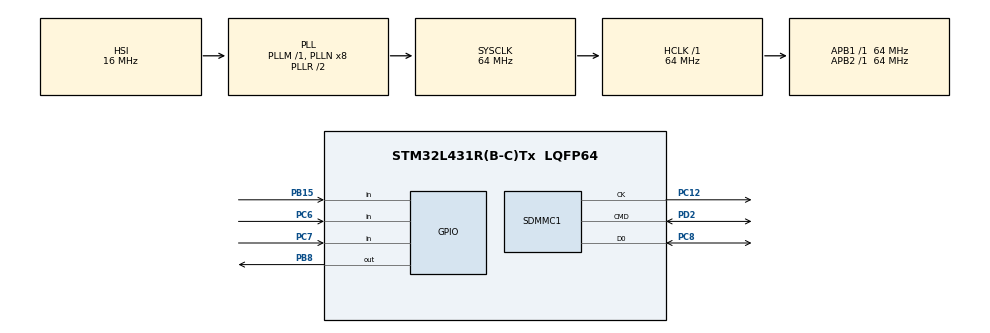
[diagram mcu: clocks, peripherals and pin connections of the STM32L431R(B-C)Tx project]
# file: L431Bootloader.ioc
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FATFS._FS_LOCK=0
FATFS._FS_MINIMIZE=3
FATFS._FS_NORTC=0
FATFS._FS_READONLY=1
FATFS._FS_TINY=1
FATFS._USE_FASTSEEK=0
FATFS._USE_LFN=0
FATFS._USE_MKFS=0
FATFS._USE_STRFUNC=0
Mcu.Family=STM32L4
Mcu.Name=STM32L431R(B-C)Tx
Mcu.Package=LQFP64
NVIC.PriorityGroup=NVIC_PRIORITYGROUP_4
PA13\ (JTMS-SWDIO).Mode=Trace_Asynchronous_SW
PA13\ (JTMS-SWDIO).Signal=SYS_JTMS-SWDIO
PA14\ (JTCK-SWCLK).Mode=Trace_Asynchronous_SW
PA14\ (JTCK-SWCLK).Signal=SYS_JTCK-SWCLK
PB15.Signal=GPIO_Input
PB3\ (JTDO-TRACESWO).Mode=Trace_Asynchronous_SW
PB3\ (JTDO-TRACESWO).Signal=SYS_JTDO-SWO
PB8.Signal=GPIO_Output
PC12.Mode=SD_1_bit
PC12.Signal=SDMMC1_CK
PC6.Signal=GPIO_Input
PC7.Signal=GPIO_Input
PC8.Mode=SD_1_bit
PC8.Signal=SDMMC1_D0
PD2.Mode=SD_1_bit
PD2.Signal=SDMMC1_CMD
ProjectManager.HeapSize=0x200
ProjectManager.StackSize=0x400
ProjectManager.TargetToolchain=STM32CubeIDE
RCC.ADCFreq_Value=64000000
RCC.AHBFreq_Value=64000000
RCC.APB1Freq_Value=64000000
RCC.APB1TimFreq_Value=64000000
RCC.APB2Freq_Value=64000000
RCC.APB2TimFreq_Value=64000000
RCC.CK48CLockSelection=RCC_USBCLKSOURCE_PLL
RCC.CortexFreq_Value=64000000
RCC.HCLKFreq_Value=64000000
RCC.HSE_VALUE=8000000
RCC.HSI48_VALUE=48000000
RCC.HSI_VALUE=16000000
RCC.LSE_VALUE=32768
RCC.MSI_VALUE=4000000
RCC.PLLQ=RCC_PLLQ_DIV8
RCC.PLLSourceVirtual=RCC_PLLSOURCE_HSI
RCC.SYSCLKFreq_VALUE=64000000
RCC.SYSCLKSource=RCC_SYSCLKSOURCE_PLLCLK
RCC.VCOOutputFreq_Value=128000000
SDMMC1.ClockDiv=2
VP_FATFS_VS_SDIO.Mode=SDIO
board=custom

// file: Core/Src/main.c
/* USER CODE BEGIN Header */
/**
  ******************************************************************************
  * @file           : main.c
  * @brief          : Main program body
  ******************************************************************************
  * @attention
  *
  * Copyright (c) 2026 STMicroelectronics.
  * All rights reserved.
  *
  * This software is licensed under terms that can be found in the LICENSE file
  * in the root directory of this software component.
  * If no LICENSE file comes with this software, it is provided AS-IS.
  *
  ******************************************************************************
  */
/* USER CODE END Header */
#include "main.h"
#include "fatfs.h"
#include "bootloader.h"
#include <stdio.h>
#include "flash_layout.h"

SD_HandleTypeDef hsd1;

void SystemClock_Config(void);
static void MX_GPIO_Init(void);
static void MX_SDMMC1_SD_Init(void);

/* USER CODE BEGIN 0 */

int _write(int file, char *ptr, int len) {
	if ((CoreDebug->DHCSR & CoreDebug_DHCSR_C_DEBUGEN_Msk) != 0) {
		for (int i = 0; i < len; i++) {
			ITM_SendChar((*ptr++));
		}

	}

	return len;
}

/* USER CODE END 0 */

int main(void)
{

  /* MCU Configuration--------------------------------------------------------*/

  /* Reset of all peripherals, Initializes the Flash interface and the Systick. */
  HAL_Init();

  /* Configure the system clock */
  SystemClock_Config();

  /* Initialize all configured peripherals */
  MX_GPIO_Init();
  MX_SDMMC1_SD_Init();
//  MX_FATFS_Init();
  /* USER CODE BEGIN 2 */

  initCRC();

  uint32_t file_crc;

  if (calculateFileCRC(&file_crc) == CRC_OK) {
	  //compare and then maybe flash.
	  uint32_t flash_crc = calculateFlashCRC();

	  if (file_crc != flash_crc) {
		  //THEN ERASE AND COPY
		  bootloader_reflash();
	  } else {
		  printf("Flash and Bootloader have same firmware!\r\n");
	  }

  } //else firmware not found or trouble mounting uSD
  //Boot normally!

  bootloader_jump_to_app();

  //BOOT NORMALLY

  /* USER CODE END 2 */

  /* Infinite loop */
  while (1)
  {

  }
}

void SystemClock_Config(void)
{
  RCC_OscInitTypeDef RCC_OscInitStruct = {0};
  RCC_ClkInitTypeDef RCC_ClkInitStruct = {0};

  /** Configure the main internal regulator output voltage
  */
  if (HAL_PWREx_ControlVoltageScaling(PWR_REGULATOR_VOLTAGE_SCALE1) != HAL_OK)
  {
    Error_Handler();
  }

  /** Initializes the RCC Oscillators according to the specified parameters
  * in the RCC_OscInitTypeDef structure.
  */
  RCC_OscInitStruct.OscillatorType = RCC_OSCILLATORTYPE_HSI;
  RCC_OscInitStruct.HSIState = RCC_HSI_ON;
  RCC_OscInitStruct.HSICalibrationValue = RCC_HSICALIBRATION_DEFAULT;
  RCC_OscInitStruct.PLL.PLLState = RCC_PLL_ON;
  RCC_OscInitStruct.PLL.PLLSource = RCC_PLLSOURCE_HSI;
  RCC_OscInitStruct.PLL.PLLM = 1;
  RCC_OscInitStruct.PLL.PLLN = 8;
  RCC_OscInitStruct.PLL.PLLP = RCC_PLLP_DIV7;
  RCC_OscInitStruct.PLL.PLLQ = RCC_PLLQ_DIV8;
  RCC_OscInitStruct.PLL.PLLR = RCC_PLLR_DIV2;
  if (HAL_RCC_OscConfig(&RCC_OscInitStruct) != HAL_OK)
  {
    Error_Handler();
  }

  /** Initializes the CPU, AHB and APB buses clocks
  */
  RCC_ClkInitStruct.ClockType = RCC_CLOCKTYPE_HCLK|RCC_CLOCKTYPE_SYSCLK
                              |RCC_CLOCKTYPE_PCLK1|RCC_CLOCKTYPE_PCLK2;
  RCC_ClkInitStruct.SYSCLKSource = RCC_SYSCLKSOURCE_PLLCLK;
  RCC_ClkInitStruct.AHBCLKDivider = RCC_SYSCLK_DIV1;
  RCC_ClkInitStruct.APB1CLKDivider = RCC_HCLK_DIV1;
  RCC_ClkInitStruct.APB2CLKDivider = RCC_HCLK_DIV1;

  if (HAL_RCC_ClockConfig(&RCC_ClkInitStruct, FLASH_LATENCY_3) != HAL_OK)
  {
    Error_Handler();
  }
}

static void MX_SDMMC1_SD_Init(void)
{

  hsd1.Instance = SDMMC1;
  hsd1.Init.ClockEdge = SDMMC_CLOCK_EDGE_RISING;
  hsd1.Init.ClockBypass = SDMMC_CLOCK_BYPASS_DISABLE;
  hsd1.Init.ClockPowerSave = SDMMC_CLOCK_POWER_SAVE_DISABLE;
  hsd1.Init.BusWide = SDMMC_BUS_WIDE_1B;
  hsd1.Init.HardwareFlowControl = SDMMC_HARDWARE_FLOW_CONTROL_DISABLE;
  hsd1.Init.ClockDiv = 2;

}

static void MX_GPIO_Init(void)
{
  GPIO_InitTypeDef GPIO_InitStruct = {0};

  /* GPIO Ports Clock Enable */
  __HAL_RCC_GPIOB_CLK_ENABLE();
  __HAL_RCC_GPIOC_CLK_ENABLE();
  __HAL_RCC_GPIOA_CLK_ENABLE();
  __HAL_RCC_GPIOD_CLK_ENABLE();

  /*Configure GPIO pin Output Level */
  HAL_GPIO_WritePin(GPIOB, GPIO_PIN_8, GPIO_PIN_RESET);

  /*Configure GPIO pin : PB15 */
  GPIO_InitStruct.Pin = GPIO_PIN_15;
  GPIO_InitStruct.Mode = GPIO_MODE_INPUT;
  GPIO_InitStruct.Pull = GPIO_NOPULL;
  HAL_GPIO_Init(GPIOB, &GPIO_InitStruct);

  /*Configure GPIO pins : PC6 PC7 */
  GPIO_InitStruct.Pin = GPIO_PIN_6|GPIO_PIN_7;
  GPIO_InitStruct.Mode = GPIO_MODE_INPUT;
  GPIO_InitStruct.Pull = GPIO_NOPULL;
  HAL_GPIO_Init(GPIOC, &GPIO_InitStruct);

  /*Configure GPIO pin : PB8 */
  GPIO_InitStruct.Pin = GPIO_PIN_8;
  GPIO_InitStruct.Mode = GPIO_MODE_OUTPUT_PP;
  GPIO_InitStruct.Pull = GPIO_NOPULL;
  GPIO_InitStruct.Speed = GPIO_SPEED_FREQ_LOW;
  HAL_GPIO_Init(GPIOB, &GPIO_InitStruct);

}

void Error_Handler(void)
{
  __disable_irq();
  while (1)
  {
  }
}
